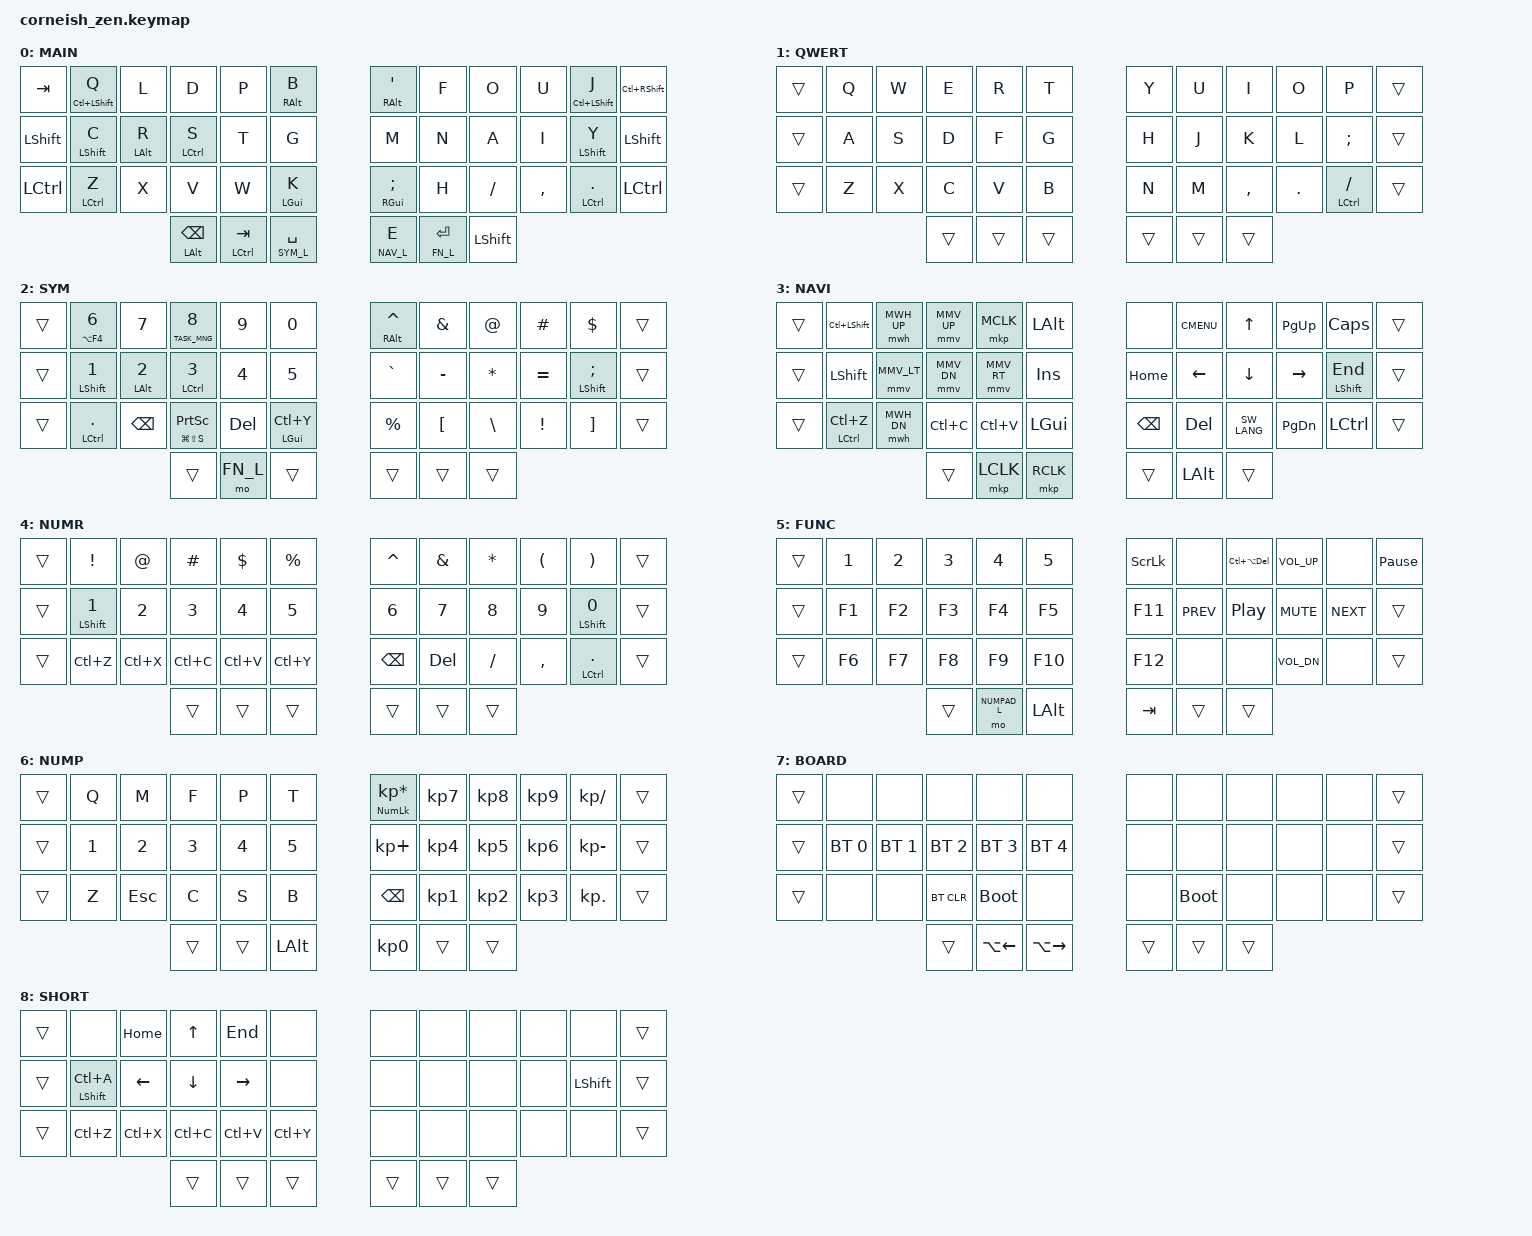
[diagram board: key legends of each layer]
#include <behaviors.dtsi>
#include <dt-bindings/zmk/bt.h>
#include <dt-bindings/zmk/keys.h>
#include <dt-bindings/zmk/mouse.h>

&sk {
  release-after-ms = <750>;
  quick-release;
};

&sl {
  release-after-ms = <3000>;
};

&lt {
  flavor = "balanced";
};

&key_repeat {
  usage-pages = <HID_USAGE_KEY HID_USAGE_CONSUMER>;
};

// Mouse move
&mmv {    
  time-to-max-speed-ms = <500>;
  acceleration-exponent=<1>;
};
// Mouse wheel
&mwh {    
  time-to-max-speed-ms = <2000>;
  acceleration-exponent=<0>;
}; 

#define MMV_UP MOVE_VERT(-1600)
#define MMV_DN MOVE_VERT(1600)
#define MMV_LT MOVE_HOR(-1600)
#define MMV_RT MOVE_HOR(1600)
#define MWH_UP SCROLL_VERT(20)
#define MWH_DN SCROLL_VERT(-20)
#define MWH_LT SCROLL_HOR(-20)
#define MWH_RT SCROLL_HOR(20)

#define MAIN_L   0
#define QWERTY_L 1
#define SYM_L    2
#define NAV_L    3
#define NUMROW_L 4
#define FN_L     5
#define NUMPAD_L 6
#define BOARD_L  7
#define SHCT_L   8

#define MEH LC(LA(LSHFT))
#define SW_LANG LA(LSHFT)
#define TASK_MNG LC(LS(ESC))

#define KEYS_L 0 1 2 3  4  5 12 13 14 15 16 17 24 25 26 27 28 29  // left-hand keys
#define KEYS_R 6 7 8 9 10 11 18 19 20 21 22 23 30 31 32 33 34 35  // right-hand keys
#define THUMBS 36 37 38 39 40 41                        // thumb keys
#define EXTRA_L 3 4 5 15 16 17 27 28 29                 // extra left-hand keys
#define EXTRA_R 6 7 8 18 19 20 30 31 32                 // extra right-hand keys

/ {
  chosen {
    zmk,matrix_transform = &default_transform;
    //zmk,matrix_transform = &five_column_transform;
  };

  combos {
    compatible = "zmk,combos";

    // shortcut
    #define COMBO(NAME, BINDINGS, KEYPOS, TIMEOUT) \
    combo_##NAME { \
      timeout-ms = <TIMEOUT>; \
      bindings = <BINDINGS>; \
      key-positions = <KEYPOS>; \
    };

    /*                   KEY POSITIONS  
      ╭────────────────────────╮ ╭────────────────────────╮
      │  0│  1   2   3   4   5 │ │  6   7   8   9  10 │11 │
      │ 12│ 13  14  15  16  17 │ │ 18  19  20  21  22 │23 │
      │ 24│ 25  26  27  28  29 │ │ 30  31  32  33  34 │35 │
      ╰──────────╮  36  37  38 │ │ 39  40  41  ╭──────────╯
                 ╰─────────────╯ ╰─────────────╯        */  
    COMBO(dot, &kp DOT, 13 23, 15)
    COMBO(enter, &kp ENTER, 14 15, 15)
    COMBO(escape, &kp ESCAPE, 2 3, 15)
    COMBO(swlang, &kp SW_LANG, 10 11, 30)

    COMBO(board_layer_mo, &mo BOARD_L, 17 29, 50)
    COMBO(board_layer_l, &sl BOARD_L, 25 26 27 28, 100)
    COMBO(board_layer_r, &sl BOARD_L, 31 32 33 34, 100)
    COMBO(function_layer_tg, &tog FN_L, 18 19 30 31, 50)
    COMBO(main_layer, &to MAIN_L, 13 14 15 16, 100)
    COMBO(shortcut_layer_mo, &mo SHCT_L, 37 38, 50)
    COMBO(numpad_layer_mo, &mo NUMPAD_L, 16 28, 50)
    COMBO(numpad_layer_tg, &tog NUMPAD_L, 16 17 28 29, 50)
    COMBO(numrow_layer_mo, &mo NUMROW_L, 38 39, 50)
    COMBO(qwerty_layer, &to QWERTY_L, 1 2 3 4, 100)
  };

  behaviors {
    hmt: hold-mod-tap {
      compatible = "zmk,behavior-hold-tap";
      label = "HOLD_MOD_TAP";
      #binding-cells = <2>;
      flavor = "hold-preferred";
      tapping-term-ms = <500>;
      bindings = <&kp>, <&kp>;
    };
    hml: home-row-left {
      compatible = "zmk,behavior-hold-tap";
      label = "HOME_ROW_LEFT";
      #binding-cells = <2>;
      flavor = "balanced";
      tapping-term-ms = <150>;
      quick-tap-ms = <50>;
      global-quick-tap;
      bindings = <&kp>, <&kp>;
      hold-trigger-key-positions = <KEYS_R EXTRA_L THUMBS>;
    };
    hmr: home-row-right {
      compatible = "zmk,behavior-hold-tap";
      label = "HOME_ROW_RIGHT";
      #binding-cells = <2>;
      flavor = "balanced";
      tapping-term-ms = <150>;
      quick-tap-ms = <50>;
      global-quick-tap;
      bindings = <&kp>, <&kp>;
      hold-trigger-key-positions = <KEYS_L EXTRA_R THUMBS>;
    };
    mtb: mod-tap-balanced {
      compatible = "zmk,behavior-hold-tap";
      label = "MOD_TAP_BALANCED";
      #binding-cells = <2>;
      flavor = "balanced";
      tapping-term-ms = <200>;
      bindings = <&kp>, <&kp>;
    };
  };
};

/ {
  keymap {
    compatible = "zmk,keymap";

    // MAIN
    main_layer {
      label = "MAIN";
      bindings = <
    //╭────────────────────────────────────────────────────────────────────────────────────────────────╮  ╭────────────────────────────────────────────────────────────────────────────────────────────────╮
        &kp TAB   &mtb LC(LSHFT) Q  &kp L         &kp D           &kp P             &mtb RALT B             &mtb RALT APOS          &kp F       &kp O           &kp U         &mtb LC(LSHFT) J &kp LC(RSHFT)
        &kp LSHFT &hml LSHFT C      &hml LALT R   &hml LCTRL S    &kp T             &kp G                   &kp M                   &kp N       &kp A           &kp I         &hmr LSHFT Y     &kp LSHFT
        &kp LCTRL &mtb LCTRL Z      &kp X         &kp V           &kp W             &mtb LGUI K             &mtb RGUI SEMI          &kp H       &kp SLASH       &kp COMMA     &mtb LCTRL DOT   &kp LCTRL
    /*╰─────────────────────────────────────╮*/   &mt LALT BSPC   &mt LCTRL TAB     &lt SYM_L SPACE         &lt NAV_L E             &lt FN_L ENTER &kp LSHFT       /*╭─────────────────────────────────────╯*/
    //                                      ╰──────────────────────────────────────────────────────────╯  ╰──────────────────────────────────────────────────────────╯
      >;  
    };

    qwerty_layer {
      label = "QWERT";
      bindings = < 
    //╭────────────────────────────────────────────────────────────────────────────────────────────────╮  ╭────────────────────────────────────────────────────────────────────────────────────────────────╮
        &trans      &kp Q           &kp W         &kp E           &kp R             &kp T                   &kp Y                   &kp U       &kp I           &kp O         &kp P           &trans
        &trans      &kp A           &kp S         &kp D           &kp F             &kp G                   &kp H                   &kp J       &kp K           &kp L         &kp SEMI        &trans
        &trans      &kp Z           &kp X         &kp C           &kp V             &kp B                   &kp N                   &kp M       &kp COMMA       &kp DOT       &mt LCTRL SLASH &trans
    /*╰─────────────────────────────────────╮*/   &trans          &trans            &trans                  &trans                  &trans      &trans             /*╭─────────────────────────────────────╯*/
    //                                      ╰──────────────────────────────────────────────────────────╯  ╰──────────────────────────────────────────────────────────╯
      >;      
    };

    sym_layer {
      label = "SYM";
      bindings = <
    //╭────────────────────────────────────────────────────────────────────────────────────────────────╮  ╭────────────────────────────────────────────────────────────────────────────────────────────────╮
        &trans      &hmt LA(F4) N6  &kp N7        &hmt TASK_MNG N8 &kp N9           &kp N0                  &mtb RALT CARET         &kp AMPS    &kp AT          &kp HASH      &kp DLLR        &trans
        &trans      &mtb LSHFT N1   &mtb LALT N2  &hml LCTRL N3   &kp N4            &kp N5                  &kp GRAVE               &kp MINUS   &kp STAR        &kp EQUAL     &mtb LSHFT SEMI &trans
        &trans      &mtb LCTRL DOT  &kp BSPC      &mtb LG(LS(S)) PSCRN &kp DELETE   &mtb LGUI LC(Y)         &kp PRCNT               &kp LBKT    &kp BSLH        &kp EXCL      &kp RBKT        &trans
    /*╰─────────────────────────────────────╮*/   &trans          &mo FN_L          &trans                  &trans                  &trans      &trans             /*╭─────────────────────────────────────╯*/
    //                                      ╰──────────────────────────────────────────────────────────╯  ╰──────────────────────────────────────────────────────────╯
      >;
    };

    nav_layer {
      label = "NAVI";
      bindings = <
    //╭────────────────────────────────────────────────────────────────────────────────────────────────╮  ╭────────────────────────────────────────────────────────────────────────────────────────────────╮
        &trans      &kp LC(LSHFT)    &mwh MWH_UP  &mmv MMV_UP     &mkp MCLK         &kp LALT                &none                   &kp K_CMENU &kp UP          &kp PAGE_UP   &kp CAPS        &trans
        &trans      &kp LSHFT        &mmv MMV_LT  &mmv MMV_DN     &mmv MMV_RT       &kp INSERT              &kp HOME                &kp LEFT    &kp DOWN        &kp RIGHT     &mtb LSHFT END  &trans
        &trans      &mtb LCTRL LC(Z) &mwh MWH_DN  &kp LC(C)       &kp LC(V)         &kp LGUI                &kp BACKSPACE           &kp DELETE  &kp SW_LANG     &kp PAGE_DOWN &kp LCTRL       &trans
    /*╰─────────────────────────────────────╮*/   &trans          &mkp LCLK         &mkp RCLK               &trans                  &kp LALT    &trans             /*╭─────────────────────────────────────╯*/
    //                                      ╰──────────────────────────────────────────────────────────╯  ╰──────────────────────────────────────────────────────────╯
      >; 
    };

    numrow_layer {
      label = "NUMR";
      bindings = <
    //╭────────────────────────────────────────────────────────────────────────────────────────────────╮  ╭────────────────────────────────────────────────────────────────────────────────────────────────╮
        &trans      &kp EXCL         &kp AT       &kp HASH        &kp DLLR          &kp PRCNT               &kp CARET               &kp AMPS    &kp STAR        &kp LPAR      &kp RPAR        &trans
        &trans      &mtb LSHFT N1    &kp N2       &kp N3          &kp N4            &kp N5                  &kp N6                  &kp N7      &kp N8          &kp N9        &mtb LSHFT N0   &trans
        &trans      &kp LC(Z)        &kp LC(X)    &kp LC(C)       &kp LC(V)         &kp LC(Y)               &kp BACKSPACE           &kp DELETE  &kp SLASH       &kp COMMA     &mtb LCTRL DOT  &trans
    /*╰─────────────────────────────────────╮*/   &trans          &trans            &trans                  &trans                  &trans      &trans             /*╭─────────────────────────────────────╯*/
    //                                      ╰──────────────────────────────────────────────────────────╯  ╰──────────────────────────────────────────────────────────╯
      >;
    };

    function_layer {
      label = "FUNC";
      bindings = <
    //╭────────────────────────────────────────────────────────────────────────────────────────────────╮  ╭────────────────────────────────────────────────────────────────────────────────────────────────╮
        &trans      &kp N1          &kp N2        &kp N3          &kp N4            &kp N5                  &kp SLCK                &none       &kp LC(LA(DEL)) &kp C_VOL_UP  &none           &kp PAUSE_BREAK
        &trans      &kp F1          &kp F2        &kp F3          &kp F4            &kp F5                  &kp F11                 &kp C_PREV  &kp C_PP        &kp C_MUTE    &kp C_NEXT      &trans
        &trans      &kp F6          &kp F7        &kp F8          &kp F9            &kp F10                 &kp F12                 &none       &none           &kp C_VOL_DN  &none           &trans
    /*╰─────────────────────────────────────╮*/   &trans          &mo NUMPAD_L      &kp LALT                &kp TAB                 &trans      &trans             /*╭─────────────────────────────────────╯*/
    //                                      ╰──────────────────────────────────────────────────────────╯  ╰──────────────────────────────────────────────────────────╯
       >;
    };

    numpad_layer {
      label = "NUMP";
      bindings = <
    //╭────────────────────────────────────────────────────────────────────────────────────────────────╮  ╭────────────────────────────────────────────────────────────────────────────────────────────────╮
        &trans      &kp Q           &kp M         &kp F           &kp P             &kp T                   &hmt KP_NUM KP_MULTIPLY &kp KP_N7   &kp KP_N8       &kp KP_N9     &kp KP_DIVIDE   &trans
        &trans      &kp N1          &kp N2        &kp N3          &kp N4            &kp N5                  &kp KP_PLUS             &kp KP_N4   &kp KP_N5       &kp KP_N6     &kp KP_SUBTRACT &trans
        &trans      &kp Z           &kp ESC       &kp C           &kp S             &kp B                   &kp BACKSPACE           &kp KP_N1   &kp KP_N2       &kp KP_N3     &kp KP_DOT      &trans
    /*╰─────────────────────────────────────╮*/   &trans          &trans            &kp LALT                &kp KP_N0               &trans      &trans             /*╭─────────────────────────────────────╯*/
    //                                      ╰──────────────────────────────────────────────────────────╯  ╰──────────────────────────────────────────────────────────╯
      >;
    };

    board_layer {
      label = "BOARD";
      bindings = <
    //╭────────────────────────────────────────────────────────────────────────────────────────────────╮  ╭────────────────────────────────────────────────────────────────────────────────────────────────╮
        &trans      &none           &none         &none           &none             &none                   &none                   &none       &none           &none         &none           &trans
        &trans      &bt BT_SEL 0    &bt BT_SEL 1  &bt BT_SEL 2    &bt BT_SEL 3      &bt BT_SEL 4            &none                   &none       &none           &none         &none           &trans
        &trans      &none           &none         &bt BT_CLR      &bootloader       &none                   &none                   &bootloader &none           &none         &none           &trans
    /*╰─────────────────────────────────────╮*/   &trans          &kp LA(LEFT)      &kp LA(RIGHT)           &trans                  &trans      &trans             /*╭─────────────────────────────────────╯*/
    //                                      ╰──────────────────────────────────────────────────────────╯  ╰──────────────────────────────────────────────────────────╯
      >;
    };

    shortcut_layer {
      label = "SHORT";
      bindings = <
    //╭────────────────────────────────────────────────────────────────────────────────────────────────╮  ╭────────────────────────────────────────────────────────────────────────────────────────────────╮
        &trans      &none           &kp HOME      &kp UP          &kp END           &none                   &none                   &none       &none           &none         &none           &trans
        &trans      &mtb LSHFT LC(A) &kp LEFT     &kp DOWN        &kp RIGHT         &none                   &none                   &none       &none           &none         &kp LSHFT       &trans
        &trans      &kp LC(Z)       &kp LC(X)     &kp LC(C)       &kp LC(V)         &kp LC(Y)               &none                   &none       &none           &none         &none           &trans
    /*╰─────────────────────────────────────╮*/   &trans          &trans            &trans                  &trans                  &trans      &trans             /*╭─────────────────────────────────────╯*/
    //                                      ╰──────────────────────────────────────────────────────────╯  ╰──────────────────────────────────────────────────────────╯
      >;  
    };
  };
};
